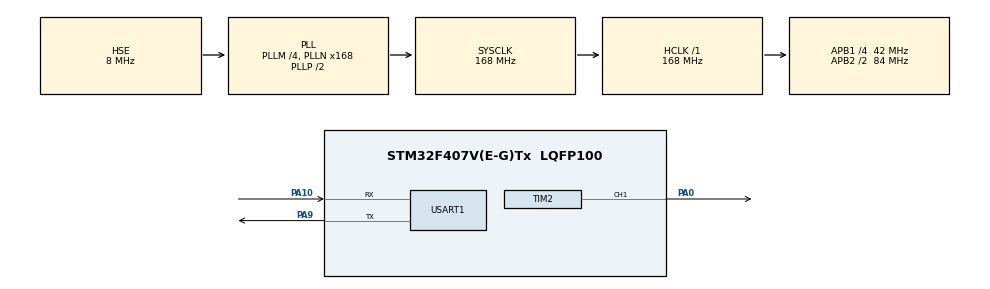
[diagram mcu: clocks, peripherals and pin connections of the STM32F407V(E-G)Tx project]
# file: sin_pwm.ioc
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Mcu.Family=STM32F4
Mcu.Name=STM32F407V(E-G)Tx
Mcu.Package=LQFP100
NVIC.PriorityGroup=NVIC_PRIORITYGROUP_4
NVIC.TIM2_IRQn=true\:0\:0\:false\:false\:true\:true\:true\:true
NVIC.USART1_IRQn=true\:0\:0\:false\:false\:true\:true\:true\:true
PA0-WKUP.Signal=S_TIM2_CH1_ETR
PA10.Mode=Asynchronous
PA10.Signal=USART1_RX
PA13.Mode=Serial_Wire
PA13.Signal=SYS_JTMS-SWDIO
PA14.Mode=Serial_Wire
PA14.Signal=SYS_JTCK-SWCLK
PA9.Mode=Asynchronous
PA9.Signal=USART1_TX
PH0-OSC_IN.Mode=HSE-External-Oscillator
PH0-OSC_IN.Signal=RCC_OSC_IN
PH1-OSC_OUT.Mode=HSE-External-Oscillator
PH1-OSC_OUT.Signal=RCC_OSC_OUT
ProjectManager.HeapSize=0x200
ProjectManager.StackSize=0x400
ProjectManager.TargetToolchain=STM32CubeIDE
RCC.48MHZClocksFreq_Value=84000000
RCC.AHBFreq_Value=168000000
RCC.APB1CLKDivider=RCC_HCLK_DIV4
RCC.APB1Freq_Value=42000000
RCC.APB1TimFreq_Value=84000000
RCC.APB2CLKDivider=RCC_HCLK_DIV2
RCC.APB2Freq_Value=84000000
RCC.APB2TimFreq_Value=168000000
RCC.CortexFreq_Value=168000000
RCC.HCLKFreq_Value=168000000
RCC.HSE_VALUE=8000000
RCC.HSI_VALUE=16000000
RCC.LSE_VALUE=32768
RCC.PLLM=4
RCC.PLLN=168
RCC.PLLSourceVirtual=RCC_PLLSOURCE_HSE
RCC.SYSCLKFreq_VALUE=168000000
RCC.SYSCLKSource=RCC_SYSCLKSOURCE_PLLCLK
RCC.VCOOutputFreq_Value=336000000
SH.S_TIM2_CH1_ETR.0=TIM2_CH1,PWM Generation1 CH1
TIM2.Channel-PWM\ Generation1\ CH1=TIM_CHANNEL_1
TIM2.Period=4199
USART1.VirtualMode=VM_ASYNC
VP_TIM2_VS_ClockSourceINT.Mode=Internal
board=custom

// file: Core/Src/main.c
/* USER CODE BEGIN Header */
/**
  ******************************************************************************
  * @file           : main.c
  * @brief          : Main program body
  ******************************************************************************
  * @attention
  *
  * Copyright (c) 2026 STMicroelectronics.
  * All rights reserved.
  *
  * This software is licensed under terms that can be found in the LICENSE file
  * in the root directory of this software component.
  * If no LICENSE file comes with this software, it is provided AS-IS.
  *
  ******************************************************************************
  */
/* USER CODE END Header */
#include "main.h"

/* USER CODE BEGIN Includes */
#include <math.h>
#include <stdlib.h>
/* USER CODE END Includes */

TIM_HandleTypeDef htim2;

UART_HandleTypeDef huart1;

/* USER CODE BEGIN PV */
#define SINE_SAMPLES 4096
uint32_t sine_lut[SINE_SAMPLES];

// Variáveis do DDS (Direct Digital Synthesis)
volatile uint32_t phase_accumulator = 0;
volatile uint32_t phase_step = 0;
volatile float frequencia_senoide = 60.0f; // Frequência inicial

// Variável para UART (Recebendo 3 caracteres, ex: "060")
uint8_t rx_buffer[3];
/* USER CODE END PV */

void SystemClock_Config(void);
static void MX_GPIO_Init(void);
static void MX_TIM2_Init(void);
static void MX_USART1_UART_Init(void);

int main(void)
{

  /* MCU Configuration--------------------------------------------------------*/

  /* Reset of all peripherals, Initializes the Flash interface and the Systick. */
  HAL_Init();

  /* Configure the system clock */
  SystemClock_Config();

  /* Initialize all configured peripherals */
  MX_GPIO_Init();
  MX_TIM2_Init();
  MX_USART1_UART_Init();
  /* USER CODE BEGIN 2 */
    // 1. Gera a LUT da senoide dinamicamente
    for (int i = 0; i < SINE_SAMPLES; i++) {
        // Ângulo de 0 a 2*PI
        float angle = (2.0f * 3.14159265f * i) / SINE_SAMPLES;

        // Seno varia de -1 a 1. Somamos 1 (fica 0 a 2), dividimos por 2 (fica 0 a 1)
        // e multiplicamos pelo ARR do timer (4199).
        sine_lut[i] = (uint32_t)(((sinf(angle) + 1.0f) / 2.0f) * 4199.0f);
    }

    // 2. Calcula o passo inicial do acumulador (para 60 Hz)
    // Fórmula: Passo = (Frequencia * 2^32) / Freq_Amostragem(20000)
    phase_step = (uint32_t)((frequencia_senoide * 4294967296.0f) / 20000.0f);

    // 3. Inicia o Timer base com interrupção e o PWM no Canal 1
    HAL_TIM_Base_Start_IT(&htim2);
    HAL_TIM_PWM_Start(&htim2, TIM_CHANNEL_1);

    // 4. Inicia a recepção da UART aguardando 3 bytes (ex: "060")
    HAL_UART_Receive_IT(&huart1, rx_buffer, 3);
  /* USER CODE END 2 */

  /* Infinite loop */
  while (1)
  {

  }
}

void SystemClock_Config(void)
{
  RCC_OscInitTypeDef RCC_OscInitStruct = {0};
  RCC_ClkInitTypeDef RCC_ClkInitStruct = {0};

  /** Configure the main internal regulator output voltage
  */
  __HAL_RCC_PWR_CLK_ENABLE();
  __HAL_PWR_VOLTAGESCALING_CONFIG(PWR_REGULATOR_VOLTAGE_SCALE1);

  /** Initializes the RCC Oscillators according to the specified parameters
  * in the RCC_OscInitTypeDef structure.
  */
  RCC_OscInitStruct.OscillatorType = RCC_OSCILLATORTYPE_HSE;
  RCC_OscInitStruct.HSEState = RCC_HSE_ON;
  RCC_OscInitStruct.PLL.PLLState = RCC_PLL_ON;
  RCC_OscInitStruct.PLL.PLLSource = RCC_PLLSOURCE_HSE;
  RCC_OscInitStruct.PLL.PLLM = 4;
  RCC_OscInitStruct.PLL.PLLN = 168;
  RCC_OscInitStruct.PLL.PLLP = RCC_PLLP_DIV2;
  RCC_OscInitStruct.PLL.PLLQ = 4;
  if (HAL_RCC_OscConfig(&RCC_OscInitStruct) != HAL_OK)
  {
    Error_Handler();
  }

  /** Initializes the CPU, AHB and APB buses clocks
  */
  RCC_ClkInitStruct.ClockType = RCC_CLOCKTYPE_HCLK|RCC_CLOCKTYPE_SYSCLK
                              |RCC_CLOCKTYPE_PCLK1|RCC_CLOCKTYPE_PCLK2;
  RCC_ClkInitStruct.SYSCLKSource = RCC_SYSCLKSOURCE_PLLCLK;
  RCC_ClkInitStruct.AHBCLKDivider = RCC_SYSCLK_DIV1;
  RCC_ClkInitStruct.APB1CLKDivider = RCC_HCLK_DIV4;
  RCC_ClkInitStruct.APB2CLKDivider = RCC_HCLK_DIV2;

  if (HAL_RCC_ClockConfig(&RCC_ClkInitStruct, FLASH_LATENCY_5) != HAL_OK)
  {
    Error_Handler();
  }
}

static void MX_TIM2_Init(void)
{

  TIM_ClockConfigTypeDef sClockSourceConfig = {0};
  TIM_MasterConfigTypeDef sMasterConfig = {0};
  TIM_OC_InitTypeDef sConfigOC = {0};

  htim2.Instance = TIM2;
  htim2.Init.Prescaler = 0;
  htim2.Init.CounterMode = TIM_COUNTERMODE_UP;
  htim2.Init.Period = 4199;
  htim2.Init.ClockDivision = TIM_CLOCKDIVISION_DIV1;
  htim2.Init.AutoReloadPreload = TIM_AUTORELOAD_PRELOAD_DISABLE;
  if (HAL_TIM_Base_Init(&htim2) != HAL_OK)
  {
    Error_Handler();
  }
  sClockSourceConfig.ClockSource = TIM_CLOCKSOURCE_INTERNAL;
  if (HAL_TIM_ConfigClockSource(&htim2, &sClockSourceConfig) != HAL_OK)
  {
    Error_Handler();
  }
  if (HAL_TIM_PWM_Init(&htim2) != HAL_OK)
  {
    Error_Handler();
  }
  sMasterConfig.MasterOutputTrigger = TIM_TRGO_RESET;
  sMasterConfig.MasterSlaveMode = TIM_MASTERSLAVEMODE_DISABLE;
  if (HAL_TIMEx_MasterConfigSynchronization(&htim2, &sMasterConfig) != HAL_OK)
  {
    Error_Handler();
  }
  sConfigOC.OCMode = TIM_OCMODE_PWM1;
  sConfigOC.Pulse = 0;
  sConfigOC.OCPolarity = TIM_OCPOLARITY_HIGH;
  sConfigOC.OCFastMode = TIM_OCFAST_DISABLE;
  if (HAL_TIM_PWM_ConfigChannel(&htim2, &sConfigOC, TIM_CHANNEL_1) != HAL_OK)
  {
    Error_Handler();
  }
  HAL_TIM_MspPostInit(&htim2);

}

static void MX_USART1_UART_Init(void)
{

  huart1.Instance = USART1;
  huart1.Init.BaudRate = 115200;
  huart1.Init.WordLength = UART_WORDLENGTH_8B;
  huart1.Init.StopBits = UART_STOPBITS_1;
  huart1.Init.Parity = UART_PARITY_NONE;
  huart1.Init.Mode = UART_MODE_TX_RX;
  huart1.Init.HwFlowCtl = UART_HWCONTROL_NONE;
  huart1.Init.OverSampling = UART_OVERSAMPLING_16;
  if (HAL_UART_Init(&huart1) != HAL_OK)
  {
    Error_Handler();
  }

}

static void MX_GPIO_Init(void)
{

  /* GPIO Ports Clock Enable */
  __HAL_RCC_GPIOH_CLK_ENABLE();
  __HAL_RCC_GPIOA_CLK_ENABLE();

}

/* USER CODE BEGIN 4 */

// --- CALLBACK DO TIMER: Executada a 20 kHz ---
void HAL_TIM_PeriodElapsedCallback(TIM_HandleTypeDef *htim)
{
  if (htim->Instance == TIM2)
  {
    // Soma o passo ao acumulador de fase
    phase_accumulator += phase_step;

    // Pega os 8 bits mais significativos (pois nossa LUT tem 256 posições)
    uint32_t lut_index = phase_accumulator >> 20;

    // Escreve direto no registrador de Capture/Compare para máxima velocidade
    TIM2->CCR1 = sine_lut[lut_index];
  }
}

// --- CALLBACK DA UART: Executada ao receber 3 bytes ---
void HAL_UART_RxCpltCallback(UART_HandleTypeDef *huart)
{
  if (huart->Instance == USART1)
  {
    // Converte os 3 bytes recebidos (ex: '0', '6', '0') para inteiro matematicamente
    int nova_freq = (rx_buffer[0] - '0') * 100 +
                    (rx_buffer[1] - '0') * 10 +
                    (rx_buffer[2] - '0');

    // Verifica os limites onde o filtro de 100nF + 3.3k (Fc = ~482Hz) é efetivo
    if (nova_freq >= 5 && nova_freq <= 120)
    {
        frequencia_senoide = (float)nova_freq;
        // Recalcula o passo do DDS com a nova frequência
        phase_step = (uint32_t)((frequencia_senoide * 4294967296.0f) / 20000.0f);
    }

    // Rearma a interrupção para continuar escutando a UART
    HAL_UART_Receive_IT(&huart1, rx_buffer, 3);
  }
}

/* USER CODE END 4 */

void Error_Handler(void)
{
  __disable_irq();
  while (1)
  {
  }
}
